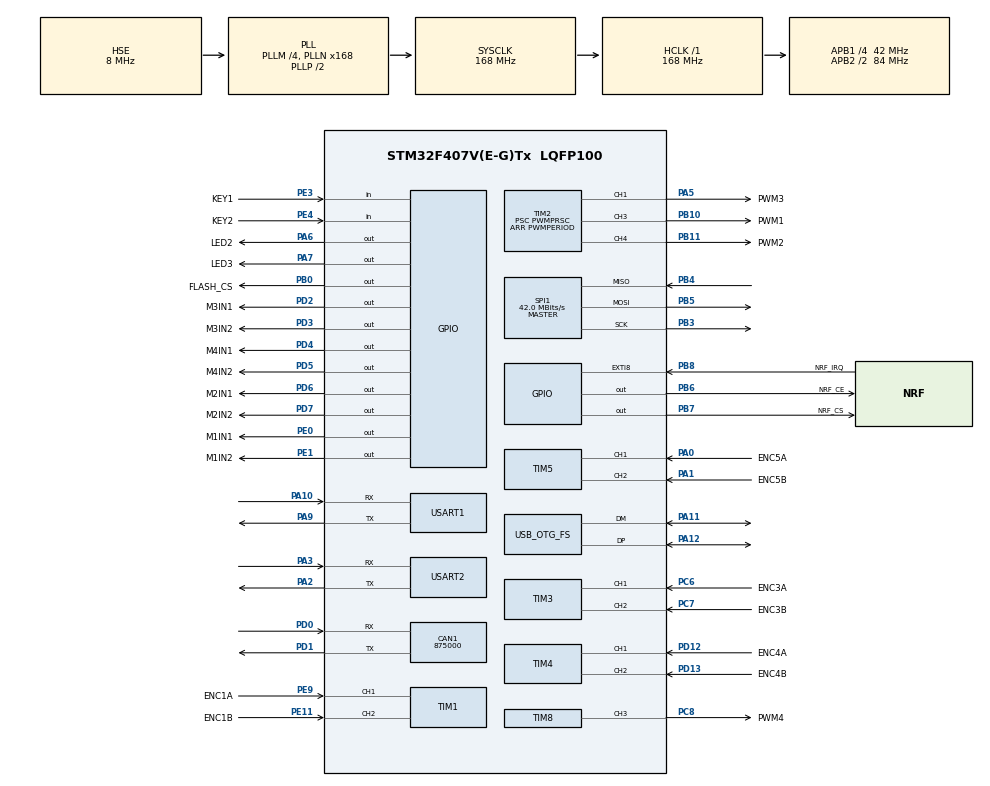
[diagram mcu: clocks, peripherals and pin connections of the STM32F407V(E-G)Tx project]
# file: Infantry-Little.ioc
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CAN1.CalculateBaudRate=875000
CAN1.CalculateTimeBit=1142
CAN1.CalculateTimeQuantum=380.95238095238096
Dma.Request0=USART2_RX
Dma.Request1=USART2_TX
Dma.USART2_RX.0.Direction=DMA_PERIPH_TO_MEMORY
Dma.USART2_RX.0.FIFOMode=DMA_FIFOMODE_DISABLE
Dma.USART2_RX.0.Instance=DMA1_Stream5
Dma.USART2_RX.0.MemDataAlignment=DMA_MDATAALIGN_BYTE
Dma.USART2_RX.0.MemInc=DMA_MINC_ENABLE
Dma.USART2_RX.0.Mode=DMA_CIRCULAR
Dma.USART2_RX.0.PeriphDataAlignment=DMA_PDATAALIGN_BYTE
Dma.USART2_RX.0.PeriphInc=DMA_PINC_DISABLE
Dma.USART2_RX.0.Priority=DMA_PRIORITY_MEDIUM
Dma.USART2_TX.1.Direction=DMA_MEMORY_TO_PERIPH
Dma.USART2_TX.1.FIFOMode=DMA_FIFOMODE_DISABLE
Dma.USART2_TX.1.Instance=DMA1_Stream6
Dma.USART2_TX.1.MemDataAlignment=DMA_MDATAALIGN_BYTE
Dma.USART2_TX.1.MemInc=DMA_MINC_ENABLE
Dma.USART2_TX.1.Mode=DMA_NORMAL
Dma.USART2_TX.1.PeriphDataAlignment=DMA_PDATAALIGN_BYTE
Dma.USART2_TX.1.PeriphInc=DMA_PINC_DISABLE
Dma.USART2_TX.1.Priority=DMA_PRIORITY_MEDIUM
FREERTOS.Tasks01=defaultTask,0,128,StartDefaultTask,Default,NULL,Dynamic,NULL,NULL;ButtonTask,0,128,StartButtonTask,Default,NULL,Dynamic,NULL,NULL
FREERTOS.configENABLE_FPU=1
FREERTOS.configLIBRARY_MAX_SYSCALL_INTERRUPT_PRIORITY=5
FREERTOS.configMAX_PRIORITIES=32
FREERTOS.configTOTAL_HEAP_SIZE=25000
Mcu.Family=STM32F4
Mcu.Name=STM32F407V(E-G)Tx
Mcu.Package=LQFP100
Mcu.UserConstants=PWMPRSC,168-1;CORECLK,168000000;PWMFREQ,15000;PWMPERIOD,CORECLK/(PWMFREQ*(PWMPRSC+1))
NVIC.CAN1_RX0_IRQn=true\:5\:0\:false\:false\:true\:true\:true\:true\:true
NVIC.CAN1_RX1_IRQn=true\:5\:0\:false\:false\:true\:true\:true\:true\:true
NVIC.DMA1_Stream5_IRQn=true\:5\:0\:false\:false\:true\:true\:false\:true\:true
NVIC.DMA1_Stream6_IRQn=true\:5\:0\:false\:false\:true\:true\:false\:true\:true
NVIC.EXTI9_5_IRQn=true\:5\:0\:true\:false\:true\:true\:true\:true\:true
NVIC.OTG_FS_IRQn=true\:5\:0\:false\:false\:true\:true\:false\:true\:true
NVIC.PriorityGroup=NVIC_PRIORITYGROUP_4
NVIC.TIM6_DAC_IRQn=true\:5\:0\:true\:false\:true\:true\:true\:true\:true
NVIC.TIM7_IRQn=true\:15\:0\:false\:false\:true\:false\:false\:true\:true
NVIC.TimeBase=TIM7_IRQn
NVIC.TimeBaseIP=TIM7
NVIC.USART1_IRQn=true\:5\:0\:true\:false\:true\:true\:true\:true\:true
NVIC.USART2_IRQn=true\:5\:0\:false\:false\:true\:true\:true\:true\:true
PA0-WKUP.GPIO_Label=ENC5A
PA0-WKUP.Signal=S_TIM5_CH1
PA1.GPIO_Label=ENC5B
PA1.Signal=S_TIM5_CH2
PA10.Mode=Asynchronous
PA10.Signal=USART1_RX
PA11.Mode=Device_Only
PA11.Signal=USB_OTG_FS_DM
PA12.Mode=Device_Only
PA12.Signal=USB_OTG_FS_DP
PA13.Mode=Serial_Wire
PA13.Signal=SYS_JTMS-SWDIO
PA14.Mode=Serial_Wire
PA14.Signal=SYS_JTCK-SWCLK
PA2.Mode=Asynchronous
PA2.Signal=USART2_TX
PA3.Mode=Asynchronous
PA3.Signal=USART2_RX
PA5.GPIO_Label=PWM3
PA5.GPIO_Speed=GPIO_SPEED_FREQ_VERY_HIGH
PA5.Signal=S_TIM2_CH1_ETR
PA6.GPIO_Label=LED2
PA6.PinState=GPIO_PIN_SET
PA6.Signal=GPIO_Output
PA7.GPIO_Label=LED3
PA7.PinState=GPIO_PIN_SET
PA7.Signal=GPIO_Output
PA9.Mode=Asynchronous
PA9.Signal=USART1_TX
PB0.GPIO_Label=FLASH_CS
PB0.GPIO_PuPd=GPIO_PULLUP
PB0.GPIO_Speed=GPIO_SPEED_FREQ_VERY_HIGH
PB0.PinState=GPIO_PIN_SET
PB0.Signal=GPIO_Output
PB10.GPIO_Label=PWM1
PB10.GPIO_Speed=GPIO_SPEED_FREQ_VERY_HIGH
PB10.Signal=S_TIM2_CH3
PB11.GPIO_Label=PWM2
PB11.GPIO_Speed=GPIO_SPEED_FREQ_VERY_HIGH
PB11.Signal=S_TIM2_CH4
PB3.Mode=Full_Duplex_Master
PB3.Signal=SPI1_SCK
PB4.Mode=Full_Duplex_Master
PB4.Signal=SPI1_MISO
PB5.Mode=Full_Duplex_Master
PB5.Signal=SPI1_MOSI
PB6.GPIO_Label=NRF_CE
PB6.GPIO_Speed=GPIO_SPEED_FREQ_VERY_HIGH
PB6.Signal=GPIO_Output
PB7.GPIO_Label=NRF_CS
PB7.GPIO_PuPd=GPIO_PULLUP
PB7.GPIO_Speed=GPIO_SPEED_FREQ_VERY_HIGH
PB7.PinState=GPIO_PIN_SET
PB7.Signal=GPIO_Output
PB8.GPIO_Label=NRF_IRQ
PB8.GPIO_ModeDefaultEXTI=GPIO_MODE_IT_FALLING
PB8.GPIO_PuPd=GPIO_PULLUP
PB8.Signal=GPXTI8
PC14-OSC32_IN.Mode=LSE-External-Oscillator
PC14-OSC32_IN.Signal=RCC_OSC32_IN
PC15-OSC32_OUT.Mode=LSE-External-Oscillator
PC15-OSC32_OUT.Signal=RCC_OSC32_OUT
PC6.GPIO_Label=ENC3A
PC6.GPIO_Speed=GPIO_SPEED_FREQ_LOW
PC6.Signal=S_TIM3_CH1
PC7.GPIO_Label=ENC3B
PC7.Signal=S_TIM3_CH2
PC8.GPIO_Label=PWM4
PC8.GPIO_Speed=GPIO_SPEED_FREQ_VERY_HIGH
PC8.Signal=S_TIM8_CH3
PD0.Mode=CAN_Activate
PD0.Signal=CAN1_RX
PD1.Mode=CAN_Activate
PD1.Signal=CAN1_TX
PD12.GPIO_Label=ENC4A
PD12.Signal=S_TIM4_CH1
PD13.GPIO_Label=ENC4B
PD13.Signal=S_TIM4_CH2
PD2.GPIO_Label=M3IN1
PD2.GPIO_Speed=GPIO_SPEED_FREQ_HIGH
PD2.Signal=GPIO_Output
PD3.GPIO_Label=M3IN2
PD3.GPIO_Speed=GPIO_SPEED_FREQ_HIGH
PD3.Signal=GPIO_Output
PD4.GPIO_Label=M4IN1
PD4.GPIO_Speed=GPIO_SPEED_FREQ_HIGH
PD4.Signal=GPIO_Output
PD5.GPIO_Label=M4IN2
PD5.GPIO_Speed=GPIO_SPEED_FREQ_HIGH
PD5.Signal=GPIO_Output
PD6.GPIO_Label=M2IN1
PD6.GPIO_Speed=GPIO_SPEED_FREQ_HIGH
PD6.Signal=GPIO_Output
PD7.GPIO_Label=M2IN2
PD7.GPIO_Speed=GPIO_SPEED_FREQ_HIGH
PD7.Signal=GPIO_Output
PE0.GPIO_Label=M1IN1
PE0.GPIO_Speed=GPIO_SPEED_FREQ_HIGH
PE0.Signal=GPIO_Output
PE1.GPIO_Label=M1IN2
PE1.GPIO_Speed=GPIO_SPEED_FREQ_HIGH
PE1.Signal=GPIO_Output
PE11.GPIO_Label=ENC1B
PE11.Signal=S_TIM1_CH2
PE3.GPIO_Label=KEY1
PE3.GPIO_PuPd=GPIO_PULLUP
PE3.Signal=GPIO_Input
PE4.GPIO_Label=KEY2
PE4.GPIO_PuPd=GPIO_PULLUP
PE4.Signal=GPIO_Input
PE9.GPIO_Label=ENC1A
PE9.Signal=S_TIM1_CH1
PH0-OSC_IN.Mode=HSE-External-Oscillator
PH0-OSC_IN.Signal=RCC_OSC_IN
PH1-OSC_OUT.Mode=HSE-External-Oscillator
PH1-OSC_OUT.Signal=RCC_OSC_OUT
ProjectManager.HeapSize=0x5000
ProjectManager.StackSize=0x5000
ProjectManager.TargetToolchain=CMake
RCC.48MHZClocksFreq_Value=48000000
RCC.AHBFreq_Value=168000000
RCC.APB1CLKDivider=RCC_HCLK_DIV4
RCC.APB1Freq_Value=42000000
RCC.APB1TimFreq_Value=84000000
RCC.APB2CLKDivider=RCC_HCLK_DIV2
RCC.APB2Freq_Value=84000000
RCC.APB2TimFreq_Value=168000000
RCC.CortexFreq_Value=168000000
RCC.HCLKFreq_Value=168000000
RCC.HSE_VALUE=8000000
RCC.HSI_VALUE=16000000
RCC.PLLM=4
RCC.PLLN=168
RCC.PLLQ=7
RCC.SYSCLKFreq_VALUE=168000000
RCC.SYSCLKSource=RCC_SYSCLKSOURCE_PLLCLK
RCC.VCOOutputFreq_Value=336000000
SH.S_TIM1_CH1.0=TIM1_CH1,Encoder_Interface
SH.S_TIM1_CH2.0=TIM1_CH2,Encoder_Interface
SH.S_TIM2_CH1_ETR.0=TIM2_CH1,PWM Generation1 CH1
SH.S_TIM2_CH3.0=TIM2_CH3,PWM Generation3 CH3
SH.S_TIM2_CH4.0=TIM2_CH4,PWM Generation4 CH4
SH.S_TIM3_CH1.0=TIM3_CH1,Encoder_Interface
SH.S_TIM3_CH2.0=TIM3_CH2,Encoder_Interface
SH.S_TIM4_CH1.0=TIM4_CH1,Encoder_Interface
SH.S_TIM4_CH2.0=TIM4_CH2,Encoder_Interface
SH.S_TIM5_CH1.0=TIM5_CH1,Encoder_Interface
SH.S_TIM5_CH2.0=TIM5_CH2,Encoder_Interface
SH.S_TIM8_CH3.0=TIM8_CH3,PWM Generation3 CH3
SPI1.BaudRatePrescaler=SPI_BAUDRATEPRESCALER_2
SPI1.CalculateBaudRate=42.0 MBits/s
SPI1.Direction=SPI_DIRECTION_2LINES
SPI1.Mode=SPI_MODE_MASTER
SPI1.VirtualType=VM_MASTER
STMicroelectronics.X-CUBE-ALGOBUILD.1.3.0.LibraryCcDSPOoLibraryJjDSPOoLibrary=true
TIM2.AutoReloadPreload=TIM_AUTORELOAD_PRELOAD_ENABLE
TIM2.Channel-PWM\ Generation1\ CH1=TIM_CHANNEL_1
TIM2.Channel-PWM\ Generation3\ CH3=TIM_CHANNEL_3
TIM2.Channel-PWM\ Generation4\ CH4=TIM_CHANNEL_4
TIM2.Period=PWMPERIOD
TIM2.Prescaler=PWMPRSC
TIM6.AutoReloadPreload=TIM_AUTORELOAD_PRELOAD_ENABLE
TIM6.Period=10000
TIM6.Prescaler=168
TIM8.AutoReloadPreload=TIM_AUTORELOAD_PRELOAD_ENABLE
TIM8.Channel-PWM\ Generation3\ CH3=TIM_CHANNEL_3
TIM8.Period=60000
TIM8.Prescaler=PWMPRSC
USART1.VirtualMode=VM_ASYNC
USART2.VirtualMode=VM_ASYNC
USB_DEVICE.CLASS_NAME_FS=CDC
USB_DEVICE.VirtualMode-CDC_FS=Cdc
USB_DEVICE.VirtualModeFS=Cdc_FS
USB_OTG_FS.VirtualMode=Device_Only
VP_CRC_VS_CRC.Mode=CRC_Activate
VP_FREERTOS_VS_CMSIS_V1.Mode=CMSIS_V1
VP_STMicroelectronics.X-CUBE-ALGOBUILD_VS_DSPOoLibraryJjLibrary_1.3.0_1.3.0.Mode=DSPOoLibraryJjLibrary
VP_SYS_VS_tim7.Mode=TIM7
VP_TIM2_VS_ClockSourceINT.Mode=Internal
VP_TIM6_VS_ClockSourceINT.Mode=Enable_Timer
VP_TIM8_VS_ClockSourceINT.Mode=Internal
VP_USB_DEVICE_VS_USB_DEVICE_CDC_FS.Mode=CDC_FS
board=custom

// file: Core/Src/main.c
/* USER CODE BEGIN Header */
/**
  ******************************************************************************
  * @file           : main.c
  * @brief          : Main program body
  ******************************************************************************
  * @attention
  *
  * Copyright (c) 2025 STMicroelectronics.
  * All rights reserved.
  *
  * This software is licensed under terms that can be found in the LICENSE file
  * in the root directory of this software component.
  * If no LICENSE file comes with this software, it is provided AS-IS.
  *
  ******************************************************************************
  */
/* USER CODE END Header */
#include "main.h"
#include "cmsis_os.h"
#include "can.h"
#include "crc.h"
#include "dma.h"
#include "spi.h"
#include "stm32f4xx_hal.h"
#include "stm32f4xx_hal_gpio.h"
#include "tim.h"
#include "usart.h"
#include "usb_device.h"
#include "gpio.h"

/* USER CODE BEGIN Includes */
#include "printf.h"
#include "robot.h"
#include "SEGGER_RTT.h"
/* USER CODE END Includes */

void SystemClock_Config(void);
void MX_FREERTOS_Init(void);

int main(void)
{

  /* MCU Configuration--------------------------------------------------------*/

  /* Reset of all peripherals, Initializes the Flash interface and the Systick. */
  HAL_Init();

  /* Configure the system clock */
  SystemClock_Config();

  /* Initialize all configured peripherals */
  MX_GPIO_Init();
  MX_DMA_Init();
  MX_USART1_UART_Init();
  MX_TIM1_Init();
  MX_TIM4_Init();
  MX_TIM2_Init();
  MX_TIM8_Init();
  MX_TIM6_Init();
  MX_SPI1_Init();
  MX_USART2_UART_Init();
  MX_TIM3_Init();
  MX_CAN1_Init();
  MX_CRC_Init();
  MX_TIM5_Init();
  /* USER CODE BEGIN 2 */
  // printf("HELLO\r\n");
  SEGGER_RTT_Init();
  RobotInit();
  SEGGER_RTT_printf(0, "HELLO!");
  /* USER CODE END 2 */

  /* Call init function for freertos objects (in cmsis_os2.c) */
  MX_FREERTOS_Init();

  /* Start scheduler */
  osKernelStart();

  /* We should never get here as control is now taken by the scheduler */

  /* Infinite loop */
  while (1)
  {

  }
}

void SystemClock_Config(void)
{
  RCC_OscInitTypeDef RCC_OscInitStruct = {0};
  RCC_ClkInitTypeDef RCC_ClkInitStruct = {0};

  /** Configure the main internal regulator output voltage
  */
  __HAL_RCC_PWR_CLK_ENABLE();
  __HAL_PWR_VOLTAGESCALING_CONFIG(PWR_REGULATOR_VOLTAGE_SCALE1);

  /** Initializes the RCC Oscillators according to the specified parameters
  * in the RCC_OscInitTypeDef structure.
  */
  RCC_OscInitStruct.OscillatorType = RCC_OSCILLATORTYPE_HSE;
  RCC_OscInitStruct.HSEState = RCC_HSE_ON;
  RCC_OscInitStruct.PLL.PLLState = RCC_PLL_ON;
  RCC_OscInitStruct.PLL.PLLSource = RCC_PLLSOURCE_HSE;
  RCC_OscInitStruct.PLL.PLLM = 4;
  RCC_OscInitStruct.PLL.PLLN = 168;
  RCC_OscInitStruct.PLL.PLLP = RCC_PLLP_DIV2;
  RCC_OscInitStruct.PLL.PLLQ = 7;
  if (HAL_RCC_OscConfig(&RCC_OscInitStruct) != HAL_OK)
  {
    Error_Handler();
  }

  /** Initializes the CPU, AHB and APB buses clocks
  */
  RCC_ClkInitStruct.ClockType = RCC_CLOCKTYPE_HCLK|RCC_CLOCKTYPE_SYSCLK
                              |RCC_CLOCKTYPE_PCLK1|RCC_CLOCKTYPE_PCLK2;
  RCC_ClkInitStruct.SYSCLKSource = RCC_SYSCLKSOURCE_PLLCLK;
  RCC_ClkInitStruct.AHBCLKDivider = RCC_SYSCLK_DIV1;
  RCC_ClkInitStruct.APB1CLKDivider = RCC_HCLK_DIV4;
  RCC_ClkInitStruct.APB2CLKDivider = RCC_HCLK_DIV2;

  if (HAL_RCC_ClockConfig(&RCC_ClkInitStruct, FLASH_LATENCY_5) != HAL_OK)
  {
    Error_Handler();
  }
}

void Error_Handler(void)
{
  __disable_irq();
  while (1)
  {
  }
}

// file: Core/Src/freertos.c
/* USER CODE BEGIN Header */
/**
  ******************************************************************************
  * File Name          : freertos.c
  * Description        : Code for freertos applications
  ******************************************************************************
  * @attention
  *
  * Copyright (c) 2025 STMicroelectronics.
  * All rights reserved.
  *
  * This software is licensed under terms that can be found in the LICENSE file
  * in the root directory of this software component.
  * If no LICENSE file comes with this software, it is provided AS-IS.
  *
  ******************************************************************************
  */
/* USER CODE END Header */

#include "FreeRTOS.h"
#include "task.h"
#include "main.h"
#include "cmsis_os.h"

/* USER CODE BEGIN Includes */
#include "gpio.h"
#include "usart.h"
#include "printf.h"
/* USER CODE END Includes */

/* USER CODE BEGIN Variables */
static uint8_t USART_RXBUFF[32];
static float Velocity[4];
/* USER CODE END Variables */
osThreadId defaultTaskHandle;
osThreadId ButtonTaskHandle;

void StartDefaultTask(void const * argument);
void StartButtonTask(void const * argument);

extern void MX_USB_DEVICE_Init(void);
void MX_FREERTOS_Init(void); /* (MISRA C 2004 rule 8.1) */

/* GetIdleTaskMemory prototype (linked to static allocation support) */
void vApplicationGetIdleTaskMemory( StaticTask_t **ppxIdleTaskTCBBuffer, StackType_t **ppxIdleTaskStackBuffer, uint32_t *pulIdleTaskStackSize );

/* USER CODE BEGIN GET_IDLE_TASK_MEMORY */
static StaticTask_t xIdleTaskTCBBuffer;
static StackType_t xIdleStack[configMINIMAL_STACK_SIZE];

void vApplicationGetIdleTaskMemory( StaticTask_t **ppxIdleTaskTCBBuffer, StackType_t **ppxIdleTaskStackBuffer, uint32_t *pulIdleTaskStackSize )
{
  *ppxIdleTaskTCBBuffer = &xIdleTaskTCBBuffer;
  *ppxIdleTaskStackBuffer = &xIdleStack[0];
  *pulIdleTaskStackSize = configMINIMAL_STACK_SIZE;
  /* place for user code */
}
/* USER CODE END GET_IDLE_TASK_MEMORY */

void MX_FREERTOS_Init(void) {

  /* Create the thread(s) */
  /* definition and creation of defaultTask */
  osThreadDef(defaultTask, StartDefaultTask, osPriorityNormal, 0, 128);
  defaultTaskHandle = osThreadCreate(osThread(defaultTask), NULL);

  /* definition and creation of ButtonTask */
  osThreadDef(ButtonTask, StartButtonTask, osPriorityNormal, 0, 128);
  ButtonTaskHandle = osThreadCreate(osThread(ButtonTask), NULL);

}

void StartDefaultTask(void const * argument)
{
  /* init code for USB_DEVICE */
  MX_USB_DEVICE_Init();
  for(;;)
  {
    osDelay(1);
  }
}

void StartButtonTask(void const * argument)
{
  /* USER CODE BEGIN StartButtonTask */
  printf("StartButtonTask");
  // HAL_UARTEx_ReceiveToIdle_DMA(&huart2, USART_RXBUFF, sizeof(USART_RXBUFF));
  // __HAL_DMA_DISABLE_IT(huart2.hdmarx, DMA_IT_HT);
  // HAL_UART_Transmit_DMA(&huart2,&"HELLO\r\n",7);
  /* Infinite loop */
  for(;;)
  {
    // LinearMapVxy(-Velocity[0],Velocity[1],Velocity[2]);
    osDelay(1);
  }
  /* USER CODE END StartButtonTask */
}

/* USER CODE BEGIN Application */
//todo 优化逻辑 接收全部32B数据
void HAL_UARTEx_RxEventCallback(UART_HandleTypeDef *huart, uint16_t Size)
{
  if(huart->Instance == USART2)
  {
    // memcpy(&Velocity[0],&USART_RXBUFF[0],sizeof(float));
    // memcpy(&Velocity[1],&USART_RXBUFF[4],sizeof(float));
    // memcpy(&Velocity[2],&USART_RXBUFF[8],sizeof(float));
    // memcpy(&Velocity[3],&USART_RXBUFF[12],sizeof(float));
    // memset(USART_RXBUFF,0,sizeof(USART_RXBUFF));
    // printf("%f,%f,%f,%f\r\n",Velocity[0],Velocity[1],Velocity[2],Velocity[3]);
    // HAL_UARTEx_ReceiveToIdle_DMA(&huart2, USART_RXBUFF, sizeof(USART_RXBUFF));
    // __HAL_DMA_DISABLE_IT(huart2.hdmarx, DMA_IT_HT);
  }
}
/* USER CODE END Application */
